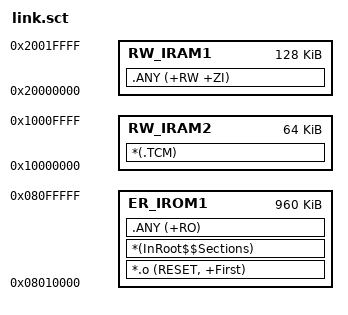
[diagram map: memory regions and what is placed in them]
; *************************************************************
; *** Scatter-Loading Description File generated by uVision ***
; *************************************************************

LR_IROM1 0x08010000 0x000F0000  {    ; 前置四个 16KB 配置区，APP 可用 960KB
  ER_IROM1 0x08010000 0x000F0000  {  ; load address = execution address
   *.o (RESET, +First)
   *(InRoot$$Sections)
   .ANY (+RO)
  }
  RW_IRAM1 0x20000000 0x00020000  {  ; RW data
   .ANY (+RW +ZI)
  }
  RW_IRAM2 0x10000000 0x00010000 {  ; RW data TCMSRAM(64KB)
   *(.TCM)
  }
}
